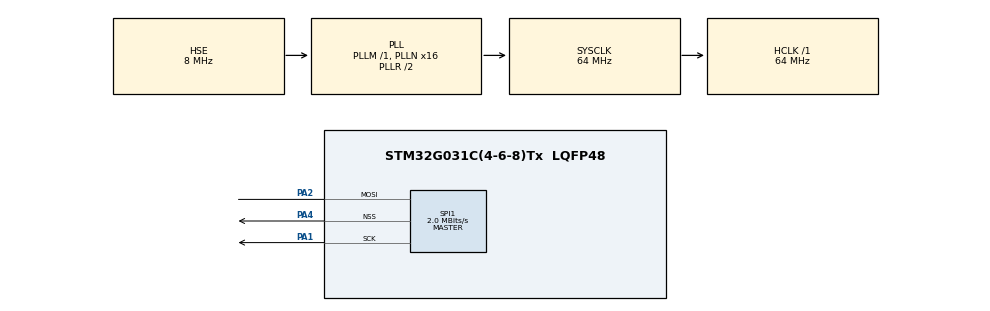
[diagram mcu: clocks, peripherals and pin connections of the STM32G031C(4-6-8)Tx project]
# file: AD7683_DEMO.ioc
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Mcu.Family=STM32G0
Mcu.Name=STM32G031C(4-6-8)Tx
Mcu.Package=LQFP48
PA1.Mode=Simplex_Bidirectional_Master
PA1.Signal=SPI1_SCK
PA2.Mode=Simplex_Bidirectional_Master
PA2.Signal=SPI1_MOSI
PA4.Mode=NSS_Signal_Hard_Output
PA4.Signal=SPI1_NSS
PF0-OSC_IN\ (PF0).Mode=HSE-External-Oscillator
PF0-OSC_IN\ (PF0).Signal=RCC_OSC_IN
PF1-OSC_OUT\ (PF1).Mode=HSE-External-Oscillator
PF1-OSC_OUT\ (PF1).Signal=RCC_OSC_OUT
ProjectManager.HeapSize=0x200
ProjectManager.StackSize=0x400
ProjectManager.TargetToolchain=MDK-ARM V5
RCC.ADCFreq_Value=64000000
RCC.AHBFreq_Value=64000000
RCC.CortexFreq_Value=64000000
RCC.EXTERNAL_CLOCK_VALUE=12288000
RCC.HCLKFreq_Value=64000000
RCC.HSE_VALUE=8000000
RCC.HSI_VALUE=16000000
RCC.PLLN=16
RCC.PLLSourceVirtual=RCC_PLLSOURCE_HSE
RCC.SYSCLKFreq_VALUE=64000000
RCC.SYSCLKSource=RCC_SYSCLKSOURCE_PLLCLK
RCC.VCOOutputFreq_Value=128000000
SPI1.BaudRatePrescaler=SPI_BAUDRATEPRESCALER_32
SPI1.CLKPhase=SPI_PHASE_2EDGE
SPI1.CLKPolarity=SPI_POLARITY_HIGH
SPI1.CalculateBaudRate=2.0 MBits/s
SPI1.Direction=SPI_DIRECTION_1LINE
SPI1.Mode=SPI_MODE_MASTER
SPI1.VirtualNSS=VM_NSSHARD
SPI1.VirtualType=VM_MASTER
board=custom

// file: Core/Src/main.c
/* USER CODE BEGIN Header */
/**
  ******************************************************************************
  * @file           : main.c
  * @brief          : Main program body
  ******************************************************************************
  * @attention
  *
  * Copyright (c) 2024 STMicroelectronics.
  * All rights reserved.
  *
  * This software is licensed under terms that can be found in the LICENSE file
  * in the root directory of this software component.
  * If no LICENSE file comes with this software, it is provided AS-IS.
  *
  ******************************************************************************
  */
/* USER CODE END Header */
#include "main.h"
#include "spi.h"
#include "gpio.h"
#include "AD7683.h"
//#include <stdalign.h>

	//_Alignas(int);

void SystemClock_Config(void);

/* USER CODE BEGIN 0 */
__align(8) int adc = 0;
__align(8) char buffer[256];
/* USER CODE END 0 */

int main(void)
{

  /* MCU Configuration--------------------------------------------------------*/

  /* Reset of all peripherals, Initializes the Flash interface and the Systick. */
  HAL_Init();

  /* Configure the system clock */
  SystemClock_Config();

  /* Initialize all configured peripherals */
  MX_GPIO_Init();
  MX_SPI1_Init();

  /* Infinite loop */
  while (1)
  {
   adc = AD7683_getADC();
  }
}

void SystemClock_Config(void)
{
  RCC_OscInitTypeDef RCC_OscInitStruct = {0};
  RCC_ClkInitTypeDef RCC_ClkInitStruct = {0};

  /** Configure the main internal regulator output voltage
  */
  HAL_PWREx_ControlVoltageScaling(PWR_REGULATOR_VOLTAGE_SCALE1);

  /** Initializes the RCC Oscillators according to the specified parameters
  * in the RCC_OscInitTypeDef structure.
  */
  RCC_OscInitStruct.OscillatorType = RCC_OSCILLATORTYPE_HSE;
  RCC_OscInitStruct.HSEState = RCC_HSE_ON;
  RCC_OscInitStruct.PLL.PLLState = RCC_PLL_ON;
  RCC_OscInitStruct.PLL.PLLSource = RCC_PLLSOURCE_HSE;
  RCC_OscInitStruct.PLL.PLLM = RCC_PLLM_DIV1;
  RCC_OscInitStruct.PLL.PLLN = 16;
  RCC_OscInitStruct.PLL.PLLP = RCC_PLLP_DIV2;
  RCC_OscInitStruct.PLL.PLLQ = RCC_PLLQ_DIV2;
  RCC_OscInitStruct.PLL.PLLR = RCC_PLLR_DIV2;
  if (HAL_RCC_OscConfig(&RCC_OscInitStruct) != HAL_OK)
  {
    Error_Handler();
  }

  /** Initializes the CPU, AHB and APB buses clocks
  */
  RCC_ClkInitStruct.ClockType = RCC_CLOCKTYPE_HCLK|RCC_CLOCKTYPE_SYSCLK
                              |RCC_CLOCKTYPE_PCLK1;
  RCC_ClkInitStruct.SYSCLKSource = RCC_SYSCLKSOURCE_PLLCLK;
  RCC_ClkInitStruct.AHBCLKDivider = RCC_SYSCLK_DIV1;
  RCC_ClkInitStruct.APB1CLKDivider = RCC_HCLK_DIV1;

  if (HAL_RCC_ClockConfig(&RCC_ClkInitStruct, FLASH_LATENCY_2) != HAL_OK)
  {
    Error_Handler();
  }
}

void Error_Handler(void)
{
  __disable_irq();
  while (1)
  {
  }
}
